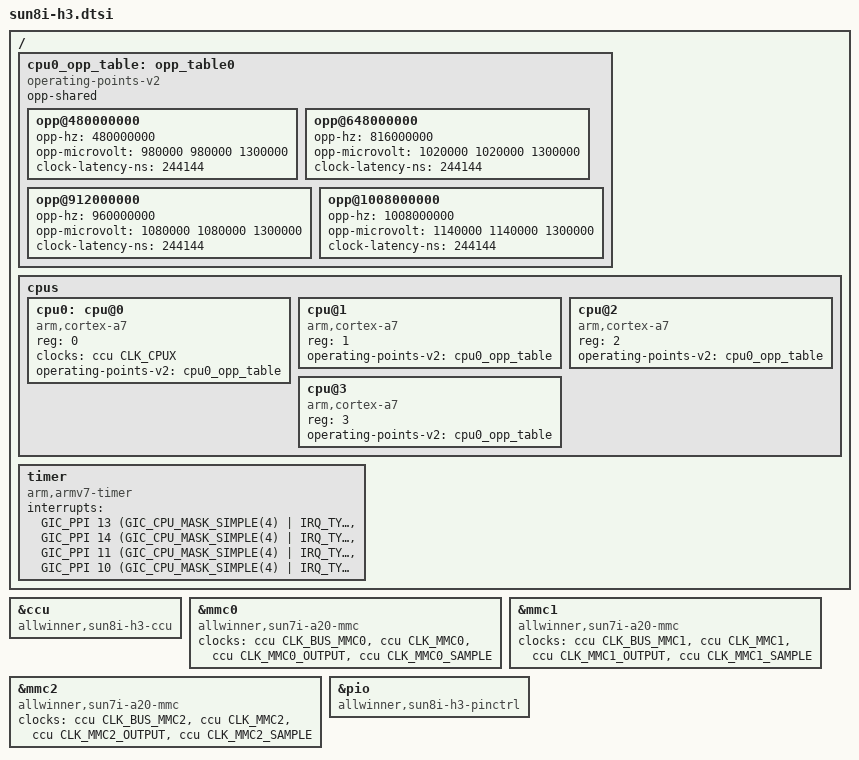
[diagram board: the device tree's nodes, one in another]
/*
 * Copyright (C) 2015 Jens Kuske <jenskuske@gmail.com>
 *
 * This file is dual-licensed: you can use it either under the terms
 * of the GPL or the X11 license, at your option. Note that this dual
 * licensing only applies to this file, and not this project as a
 * whole.
 *
 *  a) This file is free software; you can redistribute it and/or
 *     modify it under the terms of the GNU General Public License as
 *     published by the Free Software Foundation; either version 2 of the
 *     License, or (at your option) any later version.
 *
 *     This file is distributed in the hope that it will be useful,
 *     but WITHOUT ANY WARRANTY; without even the implied warranty of
 *     MERCHANTABILITY or FITNESS FOR A PARTICULAR PURPOSE.  See the
 *     GNU General Public License for more details.
 *
 * Or, alternatively,
 *
 *  b) Permission is hereby granted, free of charge, to any person
 *     obtaining a copy of this software and associated documentation
 *     files (the "Software"), to deal in the Software without
 *     restriction, including without limitation the rights to use,
 *     copy, modify, merge, publish, distribute, sublicense, and/or
 *     sell copies of the Software, and to permit persons to whom the
 *     Software is furnished to do so, subject to the following
 *     conditions:
 *
 *     The above copyright notice and this permission notice shall be
 *     included in all copies or substantial portions of the Software.
 *
 *     THE SOFTWARE IS PROVIDED "AS IS", WITHOUT WARRANTY OF ANY KIND,
 *     EXPRESS OR IMPLIED, INCLUDING BUT NOT LIMITED TO THE WARRANTIES
 *     OF MERCHANTABILITY, FITNESS FOR A PARTICULAR PURPOSE AND
 *     NONINFRINGEMENT. IN NO EVENT SHALL THE AUTHORS OR COPYRIGHT
 *     HOLDERS BE LIABLE FOR ANY CLAIM, DAMAGES OR OTHER LIABILITY,
 *     WHETHER IN AN ACTION OF CONTRACT, TORT OR OTHERWISE, ARISING
 *     FROM, OUT OF OR IN CONNECTION WITH THE SOFTWARE OR THE USE OR
 *     OTHER DEALINGS IN THE SOFTWARE.
 */

#include "sunxi-h3-h5.dtsi"

/ {
	cpu0_opp_table: opp_table0 {
		compatible = "operating-points-v2";
		opp-shared;

		opp@480000000 {
			opp-hz = /bits/ 64 <480000000>;
			opp-microvolt = <980000 980000 1300000>;
			clock-latency-ns = <244144>; /* 8 32k periods */
		};

		opp@648000000 {
			opp-hz = /bits/ 64 <816000000>;
			opp-microvolt = <1020000 1020000 1300000>;
			clock-latency-ns = <244144>; /* 8 32k periods */
		};

		opp@912000000 {
			opp-hz = /bits/ 64 <960000000>;
			opp-microvolt = <1080000 1080000 1300000>;
			clock-latency-ns = <244144>; /* 8 32k periods */
		};

		opp@1008000000 {
			opp-hz = /bits/ 64 <1008000000>;
			opp-microvolt = <1140000 1140000 1300000>;
			clock-latency-ns = <244144>; /* 8 32k periods */
		};
	};

	cpus {
		#address-cells = <1>;
		#size-cells = <0>;

		cpu0: cpu@0 {
			compatible = "arm,cortex-a7";
			device_type = "cpu";
			reg = <0>;
			clocks = <&ccu CLK_CPUX>;
			clock-names = "cpu";
			operating-points-v2 = <&cpu0_opp_table>;
			#cooling-cells = <0x2>;
		};

		cpu@1 {
			compatible = "arm,cortex-a7";
			device_type = "cpu";
			reg = <1>;
			operating-points-v2 = <&cpu0_opp_table>;
		};

		cpu@2 {
			compatible = "arm,cortex-a7";
			device_type = "cpu";
			reg = <2>;
			operating-points-v2 = <&cpu0_opp_table>;
		};

		cpu@3 {
			compatible = "arm,cortex-a7";
			device_type = "cpu";
			reg = <3>;
			operating-points-v2 = <&cpu0_opp_table>;
		};
	};

	timer {
		compatible = "arm,armv7-timer";
		interrupts = <GIC_PPI 13 (GIC_CPU_MASK_SIMPLE(4) | IRQ_TYPE_LEVEL_LOW)>,
			     <GIC_PPI 14 (GIC_CPU_MASK_SIMPLE(4) | IRQ_TYPE_LEVEL_LOW)>,
			     <GIC_PPI 11 (GIC_CPU_MASK_SIMPLE(4) | IRQ_TYPE_LEVEL_LOW)>,
			     <GIC_PPI 10 (GIC_CPU_MASK_SIMPLE(4) | IRQ_TYPE_LEVEL_LOW)>;
	};
};

&ccu {
	compatible = "allwinner,sun8i-h3-ccu";
};

&mmc0 {
	compatible = "allwinner,sun7i-a20-mmc";
	clocks = <&ccu CLK_BUS_MMC0>,
		 <&ccu CLK_MMC0>,
		 <&ccu CLK_MMC0_OUTPUT>,
		 <&ccu CLK_MMC0_SAMPLE>;
	clock-names = "ahb",
		      "mmc",
		      "output",
		      "sample";
};

&mmc1 {
	compatible = "allwinner,sun7i-a20-mmc";
	clocks = <&ccu CLK_BUS_MMC1>,
		 <&ccu CLK_MMC1>,
		 <&ccu CLK_MMC1_OUTPUT>,
		 <&ccu CLK_MMC1_SAMPLE>;
	clock-names = "ahb",
		      "mmc",
		      "output",
		      "sample";
};

&mmc2 {
	compatible = "allwinner,sun7i-a20-mmc";
	clocks = <&ccu CLK_BUS_MMC2>,
		 <&ccu CLK_MMC2>,
		 <&ccu CLK_MMC2_OUTPUT>,
		 <&ccu CLK_MMC2_SAMPLE>;
	clock-names = "ahb",
		      "mmc",
		      "output",
		      "sample";
};

&pio {
	compatible = "allwinner,sun8i-h3-pinctrl";
};
